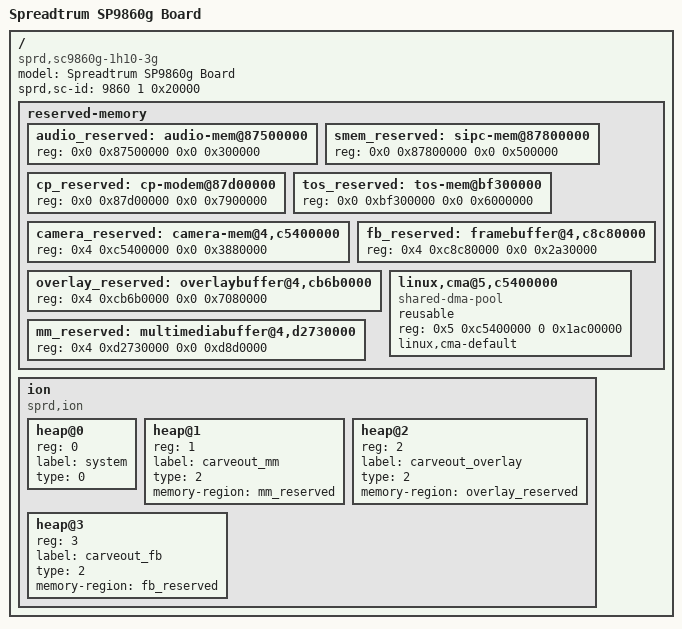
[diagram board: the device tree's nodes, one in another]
/*
 * Spreadtrum SP9860g board DTS file
 *
 * Copyright (C) 2016, Spreadtrum Communications Inc.
 *
 * This file is licensed under a dual GPLv2 or X11 license.
 */

/dts-v1/;

/ {
	model = "Spreadtrum SP9860g Board";

	compatible = "sprd,sc9860g-1h10-3g";

	sprd,sc-id = <9860 1 0x20000>;

	reserved-memory {
		#address-cells = <2>;
		#size-cells = <2>;
		ranges;

		audio_reserved: audio-mem@87500000 {
			reg = <0x0 0x87500000 0x0 0x300000>;
		};

		smem_reserved: sipc-mem@87800000 {
			reg = <0x0 0x87800000 0x0 0x500000>;
		};

		cp_reserved: cp-modem@87d00000 {
			reg = <0x0 0x87d00000 0x0 0x7900000>;
		};

		tos_reserved: tos-mem@bf300000 {
			reg = <0x0 0xbf300000 0x0 0x6000000>;
		};

		camera_reserved: camera-mem@4,c5400000{
			reg = <0x4 0xc5400000 0x0 0x3880000>;
		};

		fb_reserved: framebuffer@4,c8c80000{
			reg = <0x4 0xc8c80000 0x0 0x2a30000>;
		};

		overlay_reserved: overlaybuffer@4,cb6b0000{
			reg = <0x4 0xcb6b0000 0x0 0x7080000>;
		};

		/* For cma 4M align, enlarge its size from 0xd840000 to 0xd8d0000 */
		mm_reserved: multimediabuffer@4,d2730000{
			reg = <0x4 0xd2730000 0x0 0xd8d0000>;
		};

		/* Must 4M align */
		linux,cma@5,c5400000{
			compatible = "shared-dma-pool";
			reusable;
			reg = <0x5 0xc5400000 0 0x1ac00000>;
			linux,cma-default;
		};
	};

	ion {
		compatible = "sprd,ion";
		#address-cells = <1>;
		#size-cells = <0>;

		heap@0 {
			reg = <0>;
			label = "system";
			type = <0>;
		};

		heap@1 {
			reg = <1>;
			label = "carveout_mm";
			type = <2>;
			memory-region = <&mm_reserved>;
		};

		heap@2 {
			reg = <2>;
			label = "carveout_overlay";
			type = <2>;
			memory-region = <&overlay_reserved>;
		};

		heap@3 {
			reg = <3>;
			label = "carveout_fb";
			type = <2>;
			memory-region = <&fb_reserved>;
		};
	};
};
